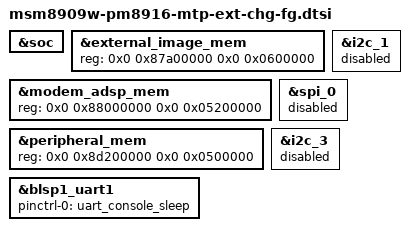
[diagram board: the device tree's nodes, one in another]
/*
 * Copyright (c) 2016, The Linux Foundation. All rights reserved.
 *
 * This program is free software; you can redistribute it and/or modify
 * it under the terms of the GNU General Public License version 2 and
 * only version 2 as published by the Free Software Foundation.
 *
 * This program is distributed in the hope that it will be useful,
 * but WITHOUT ANY WARRANTY; without even the implied warranty of
 * MERCHANTABILITY or FITNESS FOR A PARTICULAR PURPOSE.  See the
 * GNU General Public License for more details.
 */

#include "msm8909-mtp.dtsi"
#include "msm8909w-gpu.dtsi"
#include "msm8909-pm8916.dtsi"
#include "msm8909-pm8916-mtp.dtsi"
#include "msm8909w.dtsi"

&soc {
};

&external_image_mem {
	reg = <0x0 0x87a00000 0x0 0x0600000>;
};

&modem_adsp_mem {
	reg = <0x0 0x88000000 0x0 0x05200000>;
};

&peripheral_mem {
	reg = <0x0 0x8d200000 0x0 0x0500000>;
};

&blsp1_uart1 {
	status = "ok";
	pinctrl-names = "default";
	pinctrl-0 = <&uart_console_sleep>;
};

&i2c_1 {
	status = "disabled";
};

&spi_0 {
	status = "disabled";
};

&i2c_3 {
	status = "disabled";
};
